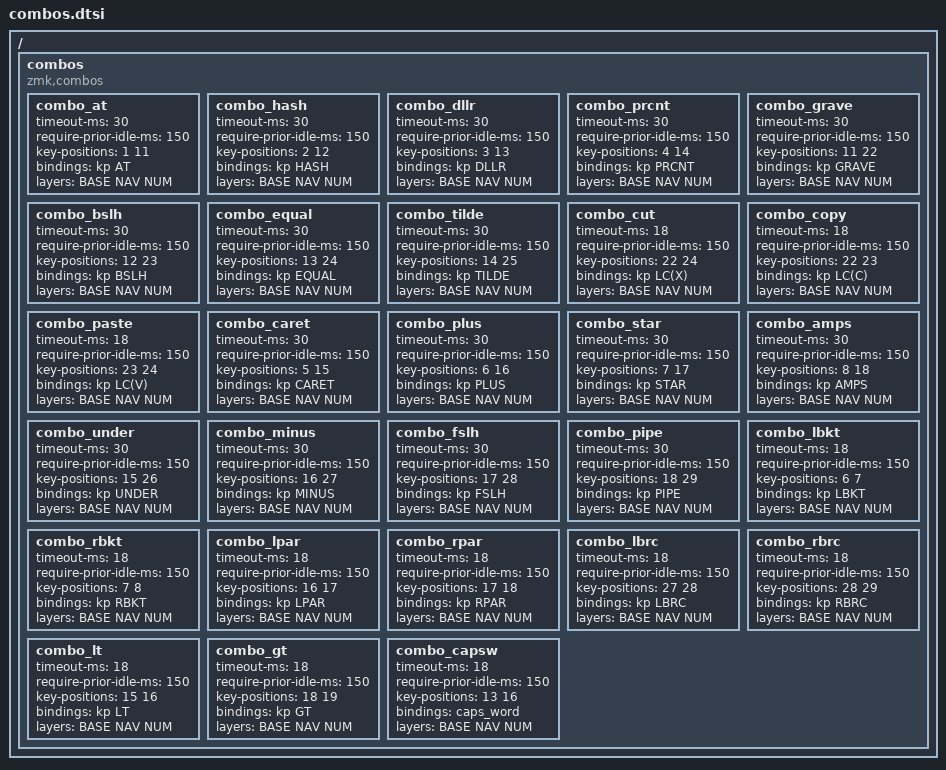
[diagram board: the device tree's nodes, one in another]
/*
 * Combos — symbols via vertical/horizontal key chords
 * Based on bsag's combo layout, adapted for Gallium.
 *
 * Position map:
 *          |  0   1   2   3   4 |  5   6   7   8   9 |
 *          | 10  11  12  13  14 | 15  16  17  18  19 |
 *     | 20 | 21  22  23  24  25 | 26  27  28  29  30 | 31 |
 *                    | 32  33  34 | 35  36  37 |
 */

/ {
    combos {
        compatible = "zmk,combos";

        // --- Left vertical combos: top + home row ---
        combo_at {
            timeout-ms = <30>;
            require-prior-idle-ms = <150>;
            key-positions = <1 11>;
            bindings = <&kp AT>;
            layers = <BASE NAV NUM>;
        };
        combo_hash {
            timeout-ms = <30>;
            require-prior-idle-ms = <150>;
            key-positions = <2 12>;
            bindings = <&kp HASH>;
            layers = <BASE NAV NUM>;
        };
        combo_dllr {
            timeout-ms = <30>;
            require-prior-idle-ms = <150>;
            key-positions = <3 13>;
            bindings = <&kp DLLR>;
            layers = <BASE NAV NUM>;
        };
        combo_prcnt {
            timeout-ms = <30>;
            require-prior-idle-ms = <150>;
            key-positions = <4 14>;
            bindings = <&kp PRCNT>;
            layers = <BASE NAV NUM>;
        };

        // --- Left vertical combos: home + bottom row ---
        combo_grave {
            timeout-ms = <30>;
            require-prior-idle-ms = <150>;
            key-positions = <11 22>;
            bindings = <&kp GRAVE>;
            layers = <BASE NAV NUM>;
        };
        combo_bslh {
            timeout-ms = <30>;
            require-prior-idle-ms = <150>;
            key-positions = <12 23>;
            bindings = <&kp BSLH>;
            layers = <BASE NAV NUM>;
        };
        combo_equal {
            timeout-ms = <30>;
            require-prior-idle-ms = <150>;
            key-positions = <13 24>;
            bindings = <&kp EQUAL>;
            layers = <BASE NAV NUM>;
        };
        combo_tilde {
            timeout-ms = <30>;
            require-prior-idle-ms = <150>;
            key-positions = <14 25>;
            bindings = <&kp TILDE>;
            layers = <BASE NAV NUM>;
        };

        // --- Left horizontal combos: clipboard (Linux: Ctrl) ---
        combo_cut {
            timeout-ms = <18>;
            require-prior-idle-ms = <150>;
            key-positions = <22 24>;
            bindings = <&kp LC(X)>;
            layers = <BASE NAV NUM>;
        };
        combo_copy {
            timeout-ms = <18>;
            require-prior-idle-ms = <150>;
            key-positions = <22 23>;
            bindings = <&kp LC(C)>;
            layers = <BASE NAV NUM>;
        };
        combo_paste {
            timeout-ms = <18>;
            require-prior-idle-ms = <150>;
            key-positions = <23 24>;
            bindings = <&kp LC(V)>;
            layers = <BASE NAV NUM>;
        };

        // --- Right vertical combos: top + home row ---
        combo_caret {
            timeout-ms = <30>;
            require-prior-idle-ms = <150>;
            key-positions = <5 15>;
            bindings = <&kp CARET>;
            layers = <BASE NAV NUM>;
        };
        combo_plus {
            timeout-ms = <30>;
            require-prior-idle-ms = <150>;
            key-positions = <6 16>;
            bindings = <&kp PLUS>;
            layers = <BASE NAV NUM>;
        };
        combo_star {
            timeout-ms = <30>;
            require-prior-idle-ms = <150>;
            key-positions = <7 17>;
            bindings = <&kp STAR>;
            layers = <BASE NAV NUM>;
        };
        combo_amps {
            timeout-ms = <30>;
            require-prior-idle-ms = <150>;
            key-positions = <8 18>;
            bindings = <&kp AMPS>;
            layers = <BASE NAV NUM>;
        };

        // --- Right vertical combos: home + bottom row ---
        combo_under {
            timeout-ms = <30>;
            require-prior-idle-ms = <150>;
            key-positions = <15 26>;
            bindings = <&kp UNDER>;
            layers = <BASE NAV NUM>;
        };
        combo_minus {
            timeout-ms = <30>;
            require-prior-idle-ms = <150>;
            key-positions = <16 27>;
            bindings = <&kp MINUS>;
            layers = <BASE NAV NUM>;
        };
        combo_fslh {
            timeout-ms = <30>;
            require-prior-idle-ms = <150>;
            key-positions = <17 28>;
            bindings = <&kp FSLH>;
            layers = <BASE NAV NUM>;
        };
        combo_pipe {
            timeout-ms = <30>;
            require-prior-idle-ms = <150>;
            key-positions = <18 29>;
            bindings = <&kp PIPE>;
            layers = <BASE NAV NUM>;
        };

        // --- Right horizontal combos: brackets ---
        combo_lbkt {
            timeout-ms = <18>;
            require-prior-idle-ms = <150>;
            key-positions = <6 7>;
            bindings = <&kp LBKT>;
            layers = <BASE NAV NUM>;
        };
        combo_rbkt {
            timeout-ms = <18>;
            require-prior-idle-ms = <150>;
            key-positions = <7 8>;
            bindings = <&kp RBKT>;
            layers = <BASE NAV NUM>;
        };
        combo_lpar {
            timeout-ms = <18>;
            require-prior-idle-ms = <150>;
            key-positions = <16 17>;
            bindings = <&kp LPAR>;
            layers = <BASE NAV NUM>;
        };
        combo_rpar {
            timeout-ms = <18>;
            require-prior-idle-ms = <150>;
            key-positions = <17 18>;
            bindings = <&kp RPAR>;
            layers = <BASE NAV NUM>;
        };
        combo_lbrc {
            timeout-ms = <18>;
            require-prior-idle-ms = <150>;
            key-positions = <27 28>;
            bindings = <&kp LBRC>;
            layers = <BASE NAV NUM>;
        };
        combo_rbrc {
            timeout-ms = <18>;
            require-prior-idle-ms = <150>;
            key-positions = <28 29>;
            bindings = <&kp RBRC>;
            layers = <BASE NAV NUM>;
        };
        combo_lt {
            timeout-ms = <18>;
            require-prior-idle-ms = <150>;
            key-positions = <15 16>;
            bindings = <&kp LT>;
            layers = <BASE NAV NUM>;
        };
        combo_gt {
            timeout-ms = <18>;
            require-prior-idle-ms = <150>;
            key-positions = <18 19>;
            bindings = <&kp GT>;
            layers = <BASE NAV NUM>;
        };

        // --- Caps word: both index fingers ---
        combo_capsw {
            timeout-ms = <18>;
            require-prior-idle-ms = <150>;
            key-positions = <13 16>;
            bindings = <&caps_word>;
            layers = <BASE NAV NUM>;
        };
    };
};
